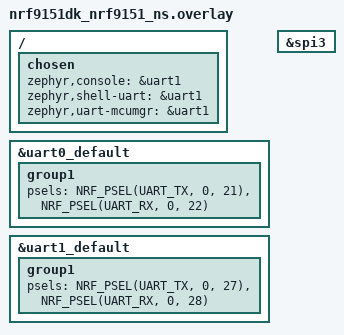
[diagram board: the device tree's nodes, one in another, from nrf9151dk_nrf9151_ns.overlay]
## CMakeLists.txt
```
# SPDX-License-Identifier: Apache-2.0

cmake_minimum_required(VERSION 3.20.0)
find_package(Zephyr REQUIRED HINTS $ENV{ZEPHYR_BASE})
project(gpsdriver)

target_sources(app PRIVATE src/main.c)
target_sources(app PRIVATE src/nmea.c)
target_sources(app PRIVATE src/gps.c)
target_sources(app PRIVATE src/shellnmea.c)
```

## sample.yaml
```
sample:
  name: LC29H GPS Module Sample
  description: |
    Demonstrates communication with LC29H GPS module via UART,
    including NMEA parsing and position data extraction.

tests:
  sample.basic.gps:
    tags:
      - GPS
      - UART
      - NMEA
    filter: dt_enabled_alias_with_parent_compat("uart0", "nordic,nrf-uarte")
    depends_on:
      - uart
      - uart_async_api
    harness: console
    timeout: 120
    min_ram: 16
    min_flash: 64
    integration_platforms:
      - nrf52840dk_nrf52840
      - nrf9160dk_nrf9160
      - nucleo_f411re
    extra_args:
      CONF_FILE: prj.conf
      OVERLAY_CONFIG: overlay-uart.conf

  sample.gps.parsing:
    tags:
      - GPS
      - NMEA
      - PARSING
    filter: dt_enabled_alias_with_parent_compat("uart0", "nordic,nrf-uarte")
    depends_on:
      - uart
      - libc
    harness: console
    integration_platforms:
      - nrf52840dk_nrf52840
      - nrf9160dk_nrf9160
    extra_args:
      CONF_FILE: prj.conf
      OVERLAY_CONFIG: overlay-gps.conf

  sample.gps.performance:
    tags:
      - GPS
      - PERFORMANCE
    filter: dt_enabled_alias_with_parent_compat("uart0", "nordic,nrf-uarte")
    depends_on:
      - timing
      - uart
    harness: console
    timeout: 180
    integration_platforms:
      - nrf52840dk_nrf52840
    extra_args:
      CONF_FILE: prj_performance.conf
```

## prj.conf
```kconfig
#
# Copyright (c) 2020 Nordic Semiconductor ASA
#
# SPDX-License-Identifier: LicenseRef-Nordic-5-Clause
#
# Use GPIO
CONFIG_GPIO=y

# General config
CONFIG_LOG=y
CONFIG_ASSERT=y
CONFIG_DEBUG=y
CONFIG_LOG_DEFAULT_LEVEL=3
CONFIG_STACK_SENTINEL=y

# Basic FPU Configuration
CONFIG_FPU=y

# LibC Configuration (use only ONE)
CONFIG_PICOLIBC=y

# Stacks and heaps
CONFIG_MAIN_STACK_SIZE=8192
CONFIG_HEAP_MEM_POOL_SIZE=32768
CONFIG_SYSTEM_WORKQUEUE_STACK_SIZE=8192

# Base serial support
CONFIG_SERIAL=y
CONFIG_UART_INTERRUPT_DRIVEN=y

# Console on UART0
CONFIG_CONSOLE=y
CONFIG_UART_CONSOLE=y

# Shell
CONFIG_SHELL=y
CONFIG_SHELL_BACKEND_SERIAL=y
CONFIG_SHELL_STACK_SIZE=2048

# For other UART operations
CONFIG_UART_ASYNC_API=y
CONFIG_RING_BUFFER=y

# Disable runtime configure unless needed
# CONFIG_UART_USE_RUNTIME_CONFIGURE=n
```

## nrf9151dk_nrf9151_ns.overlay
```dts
/{
    chosen {
                zephyr,console = &uart1;
                zephyr,shell-uart = &uart1;
                zephyr,uart-mcumgr = &uart1;};
                //zephyr,flash = <&flash0>;
                //zephyr,sram = <&sram0>;
                //zephyr,code-partition = <&slot0_ns_partition>;};
};

&uart0_default {
                    group1 {
                                psels = <NRF_PSEL(UART_TX, 0, 21)>,
                                        <NRF_PSEL(UART_RX, 0, 22)>;};
};
/delete-node/ &{/pin-controller/pwm0_default/group1/};
/delete-node/ &{/pin-controller/pwm0_sleep/group1/};
/delete-node/ &{/pin-controller/uart1_default/group1/};

&uart1_default {
    group1 {
        psels = <NRF_PSEL(UART_TX, 0, 27)>, <NRF_PSEL(UART_RX, 0, 28)>;
    };
};
/delete-node/ &{/pin-controller/uart1_default/group2/};
/delete-node/ &{/pin-controller/uart1_sleep/group1/};
/delete-node/ &{/pin-controller/uart0_default/group2/};
/delete-node/ &{/pin-controller/uart0_sleep/group1/};
/delete-node/ &{/pin-controller/spi3_default/group1/};
/delete-node/ &{/pin-controller/spi3_sleep/group1/};

&spi3 {
    /delete-property/ cs-gpios;
};
/delete-node/ &{/pin-controller/i2c2_sleep/group1/};
/delete-node/ &{/pin-controller/i2c2_default/group1/};
```

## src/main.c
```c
#include <zephyr/kernel.h>
#include <zephyr/drivers/uart.h>
#include <zephyr/drivers/gpio.h>
#include <zephyr/logging/log.h>
#include <zephyr/sys/ring_buffer.h>
#include "shellnmea.h"
#include "nmea.h"

#define RESET_PIN  23
#define WAKEUP_PIN 24
#define VCC_PIN    25
#define SENTENCE_MAX_LEN 128
#define TX_TIMEOUT_MS 1000 

LOG_MODULE_REGISTER(main, CONFIG_LOG_DEFAULT_LEVEL);

const struct device *gpio0_dev = DEVICE_DT_GET(DT_NODELABEL(gpio0));
static const struct device *const uart_dev = DEVICE_DT_GET(DT_NODELABEL(uart0));
static const struct device *const uart_dev1 = DEVICE_DT_GET(DT_NODELABEL(uart1));
static char sentence[SENTENCE_MAX_LEN];
static uint16_t sentence_idx = 0;
static volatile bool tx_done = false;

// Work queue and work item
K_THREAD_STACK_DEFINE(gnss_work_q_stack, 1024);
struct k_work_q gnss_work_q;
struct k_work gnss_work;

// Ring buffer for thread-safe data transfer
RING_BUF_DECLARE(gnss_ring_buf, 256);

#ifdef NMEA_TEST 
// Checksum calculation
static bool verify_nmea_checksum(const char *sentence)
{
    const char *asterisk = strchr(sentence, '*');
    if (!asterisk || asterisk - sentence > SENTENCE_MAX_LEN - 3) 
    {
        return false;
    }

    uint8_t checksum = 0;
    for (const char *p = sentence + 1; p < asterisk; p++) 
    {
        checksum ^= *p;
    }

    char checksum_str[3];
    checksum_str[0] = *(asterisk + 1);
    checksum_str[1] = *(asterisk + 2);
    checksum_str[2] = '\0';

    return checksum == strtoul(checksum_str, NULL, 16);
}

static void parse_nmea_sentence(const char *sentence)
{
    if (!verify_nmea_checksum(sentence)) 
    {
        LOG_WRN("Invalid checksum for: %s", sentence);
        return;
    }

    // Check sentence type
    if (strstr(sentence, "GNRMC") || strstr(sentence, "GPRMC")) {
        LOG_DBG("Unhandled NMEA sentence: %s", sentence);
    }
    else if (strstr(sentence, "GNGGA") || strstr(sentence, "GPGGA")) {
        LOG_DBG("Unhandled NMEA sentence: %s", sentence);
    }
    else {
        LOG_DBG("Unhandled NMEA sentence: %s", sentence);
    }
}
#endif

static void initialize_gps_module(void)
{
    // Configure GPIOs
    if (!device_is_ready(gpio0_dev)) 
    {
        LOG_ERR("GPIO device not ready\n");
    }
 
    // Configure all pins as outputs
    gpio_pin_configure(gpio0_dev, RESET_PIN, GPIO_OUTPUT_INACTIVE);
    gpio_pin_configure(gpio0_dev, WAKEUP_PIN, GPIO_OUTPUT_INACTIVE);
    gpio_pin_configure(gpio0_dev, VCC_PIN, GPIO_OUTPUT_INACTIVE);
 
    // Power sequence for GPS module
    // 1. Power ON GPS (if controlled via GPIO)
    gpio_pin_set(gpio0_dev, VCC_PIN, 1);
    k_msleep(100);  // Wait for power stabilization
 
    // 2. Wake up GPS (active high)
    gpio_pin_set(gpio0_dev, WAKEUP_PIN, 1);
    k_msleep(100);

    // 3. Reset sequence (active low)
    gpio_pin_set(gpio0_dev, RESET_PIN, 0);
    k_msleep(100);  // Hold reset low
    gpio_pin_set(gpio0_dev, RESET_PIN, 1);
    k_msleep(500);  // Wait for module to boot
}

static void gnss_work_cb(struct k_work *work)
{
    uint8_t data;
    size_t len;

    while ((len = ring_buf_get(&gnss_ring_buf, &data, 1)) == 1) 
    {
        if (data == '$') 
        {
            // Start of new sentence
            sentence_idx = 0;
            sentence[sentence_idx++] = data;
        }
        else if ((sentence_idx > 0) && (sentence_idx < SENTENCE_MAX_LEN - 1))
        {
            sentence[sentence_idx++] = data;
            
            // Check for complete sentence
            if (data == '\n') 
            {
                sentence[sentence_idx] = '\0';
                nmea_processing(sentence);
                sentence_idx = 0;
            }
        }
    }
}

static void uart_isr(const struct device *dev, void *user_data)
{
    ARG_UNUSED(user_data);

    if (!uart_irq_update(dev)) return;

    while (uart_irq_rx_ready(dev)) 
    {
        uint8_t byte;
        if (uart_fifo_read(dev, &byte, 1) == 1) 
        {
            if (ring_buf_put(&gnss_ring_buf, &byte, 1) != 1) 
            {
                LOG_WRN("Ring buffer full!");
            }
            k_work_submit_to_queue(&gnss_work_q, &gnss_work);
        }
    }
}

int send_nmea_message(const char *sentence)
{
    if (!device_is_ready(uart_dev)) 
    {
        LOG_ERR("UART device not ready\n");
        return -ENODEV;
    }

#ifdef NMEA_TEST
    size_t len = strlen(sentence);
    int ret;
    int attempts = 0;
    const int max_attempts = 3;

    while (attempts < max_attempts) 
    {
        // Convert timeout to milliseconds as expected by uart_tx
        ret = uart_tx(uart_dev, (const uint8_t *)sentence, len, TX_TIMEOUT_MS);
        
        if (ret == 0) 
        {
            LOG_INF("TX successful: %s", sentence);
            tx_done = true;
            return 0;
        }
        
        k_sleep(K_MSEC(100));  // Short delay between attempts
        attempts++;
    }
    LOG_ERR("Failed to send after %d attempts error: %d", max_attempts, ret);
    return -EIO;
#else
    for (int i = 0; sentence[i] != '\0'; i++) 
    {
        char ch = sentence[i];
        uart_poll_out(uart_dev, ch);

        if (sentence[i] == '\n') 
        {
            return 0;
        }
    }
#endif
    return 0;
}

int main(void)
{
    print_xtracker();

    initialize_gps_module();

    if (!device_is_ready(uart_dev)) 
    {
        LOG_ERR("UART device not ready");
        return 0;
    }

    if (!device_is_ready(uart_dev1)) 
    {
        LOG_ERR("UART1 device not ready");
        return 0;
    }
    
    nmea_init();
    
    // Initialize work queue
    k_work_queue_init(&gnss_work_q);
    k_work_queue_start(&gnss_work_q, gnss_work_q_stack,
                      K_THREAD_STACK_SIZEOF(gnss_work_q_stack),
                      CONFIG_MAIN_THREAD_PRIORITY, NULL);
    k_work_init(&gnss_work, gnss_work_cb);

    // Setup UART interrupt
    uart_irq_callback_user_data_set(uart_dev, uart_isr, NULL);
    uart_irq_rx_enable(uart_dev);
    
#ifdef NMEA_TEST 
    send_nmea_message("$PQTMVER*58\r\n");
    send_nmea_message("$PAIR062,1,1*3F\r\n");
    send_nmea_message("$PAIR062,2,1*3C\r\n");
    send_nmea_message("$PAIR062,3,1*3D\r\n");
    send_nmea_message("$PAIR062,4,1*3A\r\n");
    send_nmea_message("$PAIR062,5,1*3B\r\n");
                   
    if(tx_done == true)
    {
        send_nmea_message("$PQTMRESTOREPAR*13\r\n");
        tx_done = false;
    }

    while (1) 
    {
        k_sleep(K_SECONDS(10));
        LOG_INF("Parser still running...");
    }
#endif
}
```

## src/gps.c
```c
#include <string.h>
#include <math.h>
#include "nmea.h"
#include "gps.h"

#ifdef GPS_TEST
Location berlinLocations[] = {
    // Transport Hubs
    {"Berlin Hauptbahnhof (Central Station)", 52.5251, 13.3694},
    {"Berlin Tegel Airport (TXL)", 52.5597, 13.2877},
    {"Berlin Schönefeld Airport (SXF)", 52.3800, 13.5225},
    {"Berlin Südkreuz Station", 52.4758, 13.3653},
    
    // Landmarks
    {"Brandenburg Gate", 52.5163, 13.3777},
    {"Reichstag Building", 52.5186, 13.3763},
    {"Berlin TV Tower (Fernsehturm)", 52.5208, 13.4095},
    {"Checkpoint Charlie", 52.5075, 13.3904},
    {"Kaiser Wilhelm Memorial Church", 52.5049, 13.3348},
    
    // Parks & Recreation
    {"Tiergarten", 52.5145, 13.3501},
    {"Tempelhofer Feld", 52.4736, 13.4050},
    {"Mauerpark", 52.5440, 13.4020},
    {"Viktoriapark", 52.4886, 13.3814},
    
    // Cultural Sites
    {"Museum Island", 52.5209, 13.4017},
    {"East Side Gallery", 52.5055, 13.4403},
    {"Charlottenburg Palace", 52.5206, 13.2958},
    
    // Neighborhoods
    {"Kreuzberg (Kottbusser Tor)", 52.4990, 13.4184},
    {"Prenzlauer Berg (Kollwitzplatz)", 52.5383, 13.4193},
    {"Neukölln (Hermannplatz)", 52.4811, 13.4239},
    {"Mitte (Nikolaiviertel)", 52.5161, 13.4077},
    
    // Shopping & Dining
    {"Kurfürstendamm (Ku'damm)", 52.5022, 13.3285},
    {"Alexanderplatz", 52.5219, 13.4132},
    {"Potsdamer Platz", 52.5096, 13.3763}
};
#endif
// Number of days in each month for a non-leap year
const int days_in_month[12] = { 31,28,31,30,31,30,31,31,30,31,30,31 };

// Check if a year is a leap year
int is_leap_year(int year) 
{
    return (year % 4 == 0 && (year % 100 != 0 || year % 400 == 0));
}

void timestamp_to_datetime(uint32_t timestamp, uint16_t *year, uint8_t *month, uint8_t *day, uint8_t *hour, uint8_t *minute, uint8_t *second) 
{
    // Unix time starts at 1970-01-01 00:00:00 UTC
    int y = 1970;
    int days;

    // Extract time components from timestamp
    *second = timestamp % 60;
    timestamp /= 60;
    *minute = timestamp % 60;
    timestamp /= 60;
    *hour = timestamp % 24;
    timestamp /= 24;
    days = timestamp;  // total days since 1970-01-01

    // Calculate year
    while (1) 
    {
        int days_in_year = is_leap_year(y) ? 366 : 365;
        if (days >= days_in_year) 
        {
            days -= days_in_year;
            y++;
        } 
        else 
        {
            break;
        }
    }
    *year = y;

    // Calculate month
    int m = 0;
    while (1) 
    {
        int dim = days_in_month[m];
        if (m == 1 && is_leap_year(y)) 
        { // February in leap year
            dim = 29;
        }

        if (days >= dim) 
        {
            days -= dim;
            m++;
        } 
        else 
        {
            break;
        }
    }
    *month = m + 1;  // month is 1-based

    // Remaining days is the day of the month
    *day = days + 1; // day is 1-based
}

// Convert lat e lon to decimals (from deg)
void gps_convert_deg_to_dec(double *latitude, char ns,  double *longitude, char we)
{
    double lat = (ns == 'N') ? *latitude : -1 * (*latitude);
    double lon = (we == 'E') ? *longitude : -1 * (*longitude);

    *latitude = gps_deg_dec(lat);
    *longitude = gps_deg_dec(lon);
}

double gps_deg_dec(double deg_point)
{
    double ddeg;
    double sec = modf(deg_point, &ddeg)*60;
    int deg = (int)(ddeg/100);
    int min = (int)(deg_point-(deg*100));

    double absdlat = round(deg * 1000000.);
    double absmlat = round(min * 1000000.);
    double absslat = round(sec * 1000000.);

    return round(absdlat + (absmlat/60) + (absslat/3600)) /1000000;
}

#ifdef GPS_TEST
void gps_find_location(GNSS_Data *data)
{
    for (int i = 0; i < sizeof(berlinLocations) / sizeof(berlinLocations[0]); i++) 
    {
        double lat = berlinLocations[i].latitude;
        double lon = berlinLocations[i].longitude;

        if (fabs(lat - data->latitude) < 0.0001 && fabs(lon - data->longitude) < 0.0001) 
        {
            printf("Location: %s\n", berlinLocations[i].name);
            return;
        }
    }
    printf("Location not found.\n");
}
#endif
```

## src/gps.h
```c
#ifndef _GPS_H_
#define _GPS_H_

#include <stdio.h>
#include <stdlib.h>
#include <inttypes.h>

#ifdef GPS_TEST
// Define a structure to hold location data
typedef struct 
{
    char name[50];
    double latitude;
    double longitude;
} Location;

void gps_find_location(GNSS_Data *data);
#endif

// Initialize device
extern void gps_init(void);
// Activate device
extern void gps_on(void);
// Turn off device (low-power consumption)
extern void gps_off(void);
void timestamp_to_datetime(uint32_t timestamp, uint16_t *year, uint8_t *month, uint8_t *day, uint8_t *hour, uint8_t *minute, uint8_t *second);

// convert deg to decimal deg latitude, (N/S), longitude, (W/E)
void gps_convert_deg_to_dec(double *, char, double *, char);
double gps_deg_dec(double);

#endif
```

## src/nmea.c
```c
#include <zephyr/device.h>
#include <zephyr/drivers/uart.h>
#include <zephyr/logging/log.h>
#include <zephyr/kernel.h>
#include <string.h>
#include <math.h>
#include "nmea.h"

GNSS_Data *gnss_data = NULL;
TimeStruct UTC_time = {0};

LOG_MODULE_REGISTER(nmea, CONFIG_LOG_DEFAULT_LEVEL);

void nmea_init(void)
{
    gnss_data = malloc(sizeof(GNSS_Data));
    if (gnss_data != NULL) 
    {
        memset(gnss_data, 0, sizeof(GNSS_Data));
    }
}

// Helper function: Convert NMEA (DDMM.MMMM or DDDMM.MMMM) to decimal degrees
static double nmea_to_decimal(double nmea_coord) 
{
    int degrees = (int)(nmea_coord / 100);
    double minutes = nmea_coord - (degrees * 100);
    return degrees + (minutes / 60.0);
}

TimeStruct nmea_parse_time(const char* time_str)
{
    TimeStruct time = {0};
    time.valid = false;

    if ((time_str == NULL) || (strlen(time_str) < 6))
    {
        return time;  // Invalid time format
    }

    // Example time format: "123456.78" (hhmmss.sss)
    char buffer[3] = {0};
    
    // Extract hours (first 2 digits)
    strncpy(buffer, time_str, 2);
    time.hours = atoi(buffer);
    
    // Extract minutes (next 2 digits)
    strncpy(buffer, time_str + 2, 2);
    time.minutes = atoi(buffer);
    
    // Extract seconds (next 2 digits)
    strncpy(buffer, time_str + 4, 2);
    time.seconds = atoi(buffer);
    
    // Find decimal point for hundredths
    const char* decimal_ptr = strchr(time_str, '.');
    if ((decimal_ptr != NULL) && (strlen(decimal_ptr) > 1))
    {
        // Take up to 2 digits after decimal
        strncpy(buffer, decimal_ptr + 1, 2);
        time.millis = atoi(buffer);
    }
    
    // Validate ranges
    if (time.hours < 24 && time.minutes < 60 && time.seconds < 60) 
    {
        time.valid = true;
    }

    // Combine into uint32_t timestamp (hhmmsshh format)
    return time;
}

void nmea_parse_gpgga(const char *nmea)
{
    char *token; 
    char copy[NMEA_MAX_LEN];
    SAFE_STRNCPY(copy, nmea, sizeof(copy));

    token = strtok(copy, ",");
    int field = 0;
    
    while (token != NULL) 
    {
        switch (field) 
        {
            case 1:  // Timestamp (HHMMSS.SSS)
                UTC_time = nmea_parse_time(token);
                break;
            case 2:  // Latitude (DDMM.MMMM)
                gnss_data->latitude = nmea_to_decimal(atof(token));
                break;
            case 3:  // Latitude direction (N/S)
                if (*token == 'S') gnss_data->latitude *= -1;
                break;
            case 4:  // Longitude (DDDMM.MMMM)
                gnss_data->longitude = nmea_to_decimal(atof(token));
                break;
            case 5:  // Longitude direction (E/W)
                if (*token == 'W') gnss_data->longitude *= -1;
                break;
            case 7:  // Satellites in use
                gnss_data->satellites = atoi(token);
                break;
            case 9:  // Altitude (meters)
                gnss_data->altitude = atof(token);
                break;
        }
        token = strtok(NULL, ",");
        field++;
    }
}

void nmea_parse_gprmc(const char *nmea)
{
    char *token;
    char copy[NMEA_MAX_LEN];
    SAFE_STRNCPY(copy, nmea, sizeof(copy));

    token = strtok(copy, ",");
    int field = 0;
    
    while (token != NULL) 
    {
        switch (field) 
        {
            case 1:  // Timestamp (HHMMSS.SSS)
                UTC_time = nmea_parse_time(token);
                break;
            case 2:  // Status (A=active, V=void)
                //gnss_data->status = *token;
                break;
            case 3:  // Latitude (DDMM.MMMM)
                gnss_data->latitude = nmea_to_decimal(atof(token));
                break;
            case 4:  // Latitude direction (N/S)
                if (*token == 'S') gnss_data->latitude *= -1;
                break;
            case 5:  // Longitude (DDDMM.MMMM)
                gnss_data->longitude = nmea_to_decimal(atof(token));
                break;
            case 6:  // Longitude direction (E/W)
                if (*token == 'W') gnss_data->longitude *= -1;
                break;
            case 7:  // Speed (knots)
                // Can be parsed if needed
                break;
        }
        token = strtok(NULL, ",");
        field++;
    }
}

void nmea_parse_gngga(const char *nmea)
{
    char copy[NMEA_MAX_LEN];
    SAFE_STRNCPY(copy, nmea, sizeof(copy));

    char *token = strtok(copy, ",");
    int field = 0;

    while (token != NULL) 
    {
        switch (field) 
        {
            case 1: // Time
                UTC_time = nmea_parse_time(token);
                break;
            case 2: // Latitude
                gnss_data->latitude = nmea_to_decimal(atof(token));
                break;
            case 3: // N/S Indicator
                //gnss_data->ns_indicator = *token;
                //if (*token == 'S') gnss_data->latitude *= -1;
                break;
            case 4: // Longitude
                gnss_data->longitude = nmea_to_decimal(atof(token));
                break;
            case 5: // E/W Indicator
                //gnss_data->ew_indicator = *token;
                //if (*token == 'W') gnss_data->longitude *= -1;
                break;
            case 6: // Fix Quality
                gnss_data->fix_quality = atoi(token);
                break;
            case 7: // Number of Satellites
                //gnss_data->num_satellites = atoi(token);
                break;
            case 8: // HDOP
                //gnss_data->hdop = atof(token);
                break;
            case 9: // Altitude
                gnss_data->altitude = atof(token);
                break;
            case 10: // Altitude Units
                //gnss_data->altitude_units = *token;
                break;
            case 11: // Geoid Separation
                //gnss_data->geoid_separation = atof(token);
                break;
            case 12: // Geoid Units
                //gnss_data->geoid_units = *token;
                break;
            case 13: // Age of Differential Correction
                //SAFE_STRNCPY(gnss_data->age_of_diff_corr, token, sizeof(gnss_data->age_of_diff_corr));
                break;
            case 14: // Diff Ref Station ID
                //SAFE_STRNCPY(gnss_data->diff_ref_station_id, token, sizeof(gnss_data->diff_ref_station_id));
                break;
        }
        token = strtok(NULL, ",");
        field++;
    }
}

#ifdef GSA
void nmea_parse_gpgsa(const char *nmea) 
{
    char *token;
    char copy[NMEA_MAX_LEN];
    SAFE_STRNCPY(copy, nmea, sizeof(copy));

    token = strtok(copy, ",");
    int field = 0;
    
    while (token != NULL) 
    {
        switch (field) 
        {
            case 2:  // Fix Type (1=No fix, 2=2D, 3=3D)
                gnss_data->fix_quality = atoi(token);
                break;
            case 15: // PDOP
                gnss_data->pdop = atof(token);
                break;
            case 16: // HDOP
                gnss_data->hdop = atof(token);
                break;
            case 17: // VDOP
                gnss_data->vdop = atof(token);
                break;
        }
        token = strtok(NULL, ",");
        field++;
    }
}
#endif

#ifdef GSV
void nmea_parse_gpgsv(const char *nmea) 
{
    char *token;
    char copy[NMEA_MAX_LEN];
    SAFE_STRNCPY(copy, nmea, sizeof(copy));

    token = strtok(copy, ",");
    int field = 0;
    int sat_index = 0;
    
    while (token != NULL) 
    {
        switch (field) 
        {
            case 3:  // Total Satellites in View
                gnss_data->total_sats_in_view = atoi(token);
                break;
            case 4:  // Satellite PRN (first of up to 4 per message)
            case 8:  // Second satellite
            case 12: // Third satellite
            case 16: // Fourth satellite
                if (sat_index < 24) 
                {
                    gnss_data->sat_info[sat_index].prn = atoi(token);
                    sat_index++;
                }
                break;
            case 5:  // Elevation (first satellite)
            case 9:  // Second satellite
            case 13: // Third satellite
            case 17: // Fourth satellite
                if (sat_index > 0) 
                {
                    gnss_data->sat_info[sat_index-1].elevation = atoi(token);
                }
                break;
            case 6:  // Azimuth (first satellite)
            case 10: // Second satellite
            case 14: // Third satellite
            case 18: // Fourth satellite
                if (sat_index > 0) 
                {
                    gnss_data->sat_info[sat_index-1].azimuth = atoi(token);
                }
                break;
            case 7:  // SNR (first satellite)
            case 11: // Second satellite
            case 15: // Third satellite
            case 19: // Fourth satellite
                if (sat_index > 0) 
                {
                    gnss_data->sat_info[sat_index-1].snr = atoi(token);
                }
                break;
        }
        token = strtok(NULL, ",");
        field++;
    }
}
#endif

#ifdef VTG
void nmea_parse_gpvtg(const char *nmea) 
{
    char *token;
    char copy[NMEA_MAX_LEN];
    SAFE_STRNCPY(copy, nmea, sizeof(copy));

    token = strtok(copy, ",");
    int field = 0;
    
    while (token != NULL) 
    {
        switch (field) 
        {
            case 1:  // True Course (degrees)
                gnss_data->course = atof(token);
                break;
            case 7:  // Speed (km/h)
                gnss_data->speed = atof(token);
                break;
        }
        token = strtok(NULL, ",");
        field++;
    }
}
#endif

#ifdef GLL
void nmea_parse_gpgll(const char *nmea) 
{
    char *token;
    char copy[NMEA_MAX_LEN];
    SAFE_STRNCPY(copy, nmea, sizeof(copy));

    token = strtok(copy, ",");
    int field = 0;
    
    while (token != NULL) 
    {
        switch (field) 
        {
            case 1:  // Latitude (DDMM.MMMM)
                gnss_data->latitude = atof(token) / 100.0;
                break;
            case 2:  // N/S
                if (*token == 'S') gnss_data->latitude *= -1;
                break;
            case 3:  // Longitude (DDDMM.MMMM)
                gnss_data->longitude = atof(token) / 100.0;
                break;
            case 4:  // E/W
                if (*token == 'W') gnss_data->longitude *= -1;
                break;
            case 5:  // UTC Time (HHMMSS.SSS)
                SAFE_STRNCPY(gnss_data->timestamp, token, sizeof(gnss_data->timestamp));
                break;
            case 6:  // Status (A=Valid, V=Invalid)
                gnss_data->fix_quality = (*token == 'A') ? 1 : 0;
                break;
        }
        token = strtok(NULL, ",");
        field++;
    }
}
#endif
void parse_pqverno(const char *sentence) 
{
    char copy[NMEA_MAX_LEN];
    SAFE_STRNCPY(copy, sentence, sizeof(copy));
    copy[sizeof(copy)-1] = '\0';

    char *token = strtok(copy, ",");
    int index = 0;
    while (token != NULL) 
    {
        if (index == 2) 
        {  // SW Version is usually the 3rd token
            strncpy(gnss_data->firmware_version, token, sizeof(gnss_data->firmware_version));
            gnss_data->firmware_version[sizeof(gnss_data->firmware_version)-1] = '\0';
            break;
        }
        token = strtok(NULL, ",");
        index++;
    }
}

uint8_t nmea_valid_checksum(const char *sentence) 
{
    uint8_t checksum= (uint8_t)strtol(strchr(sentence, '*')+1, NULL, 16);

    char p;
    uint8_t sum = 0;
    ++sentence;
    while ((p = *sentence++) != '*') 
    {
        sum ^= p;
    }

    if (sum != checksum) 
    {
        return NMEA_CHECKSUM_ERROR;
    }

    return _EMPTY;
}

NMEA_MessageType nmea_get_message_type(const char *sentence) 
{
    char *token;
    char copy[NMEA_MAX_LEN];
    SAFE_STRNCPY(copy, sentence, sizeof(copy));
    // Validate checksum first
    uint8_t checksum_status = nmea_valid_checksum(sentence);
    if (checksum_status == NMEA_CHECKSUM_ERROR) 
    {
        return NMEA_CHECKSUM_ERROR;
    }
    
    token = strtok(copy, ",");

    // Detect token type
    if (strstr(token, NMEA_GPGGA_WORD) != NULL) return NMEA_GPGGA;
    if (strstr(token, NMEA_GPRMC_WORD) != NULL) return NMEA_GPRMC;
    if (strstr(token, NMEA_GNGGA_WORD) != NULL) return NMEA_GNGGA;
    //if (strstr(token, NMEA_GPVTG_WORD) != NULL) return NMEA_GPVTG;
    //if (strstr(token, NMEA_GPGSA_WORD) != NULL) return NMEA_GPGSA;
    //if (strstr(token, NMEA_GPGSV_WORD) != NULL) return NMEA_GPGSV;
    //if (strstr(token, NMEA_GPGLL_WORD) != NULL) return NMEA_GPGLL;
    //if (strstr(token, NMEA_GPZDA_WORD) != NULL) return NMEA_GPZDA;
    //if (strstr(token, NMEA_GPGST_WORD) != NULL) return NMEA_GPGST;
    //if (strstr(token, NMEA_GPGNS_WORD) != NULL) return NMEA_GPGNS;
    if (strstr(token, NMEA_PQVERNO_WORD) != NULL) return NMEA_PQVERNO;

    return NMEA_UNKNOWN;
}

static void handle_unknown(const char *sentence) 
{
    char buffer[16]; // Local buffer to store the sentence type
 
    // Extract the first part of the sentence (e.g., "$GPGGA")
    const char *delimiter = strchr(sentence, ','); // Find the first comma
    if (delimiter != NULL)
    {
        size_t length = delimiter - sentence; // Calculate the length of the sentence type
        if (length >= sizeof(buffer))
        {
            length = sizeof(buffer) - 1; // Ensure we don't overflow the buffer
        }
        strncpy(buffer, sentence, length); // Copy the sentence type to buffer
        buffer[length] = '\0'; // Null-terminate the string
    } 
    else 
    {
        strncpy(buffer, sentence, sizeof(buffer) - 1); // Handle case with no comma
        buffer[sizeof(buffer) - 1] = '\0'; // Null-terminate the string
    }
 
    LOG_DBG("UNKNOWN: %s\n", buffer); // Print the extracted sentence type
}

/* NMEA Processing */
void nmea_processing(const char *sentence)
{
    uint8_t msgtype;
     
    // Dispatch to appropriate handler
    msgtype = nmea_get_message_type(sentence);
    if (msgtype == NMEA_CHECKSUM_ERROR) 
    {
        return;
    }
    
    switch (msgtype) 
    {
        case NMEA_GPGGA:
            nmea_parse_gpgga(sentence);
        break;
        case NMEA_GPRMC:
            nmea_parse_gprmc(sentence);
        break;
        case NMEA_GNGGA:
            nmea_parse_gngga(sentence);
        break;
        case NMEA_GPGLL:
        case NMEA_GPGSV:
        case NMEA_GPGSA:
        case NMEA_GPGST:
        case NMEA_GPZDA:
        case NMEA_GPGNS:
            handle_unknown(sentence);
        break;
        case NMEA_PQVERNO:
            parse_pqverno(sentence);
        break;
        default:
            // Unhandled message type
            handle_unknown(sentence);
        break;
    }
}

void nmea_enable_pps_sync(void)
{
	//uint8_t buffer[] = NMEA_ENABLE_PPS_SYNC;
	//send_nmea_message(buffer);
}

void nmea_hot_restart(void)
{
	//uint8_t buffer[] = NMEA_HOT_RST_CMD;
	//send_nmea_message(buffer);
}

void nmea_factory_reset(void)
{
	//uint8_t buffer[] = NMEA_FCOLD_RST_CMD;
	//send_nmea_message(buffer);
}

void nmea_standby(void)
{
	//uint8_t buffer[] = NMEA_SET_STDBY_CMD;
	//send_nmea_message(buffer);
}
```

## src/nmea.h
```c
#ifndef _NMEA_H_
#define _NMEA_H_

#include <stdio.h>
#include <stdlib.h>
#include <inttypes.h>
#include <stdbool.h>

/* NMEA Command Macros */
#define _EMPTY 0x00
#define _COMPLETED 0x03
#define NMEA_MESSAGE_ERR 0xC0
#define NMEA_MAX_LEN 82

/* LC29H-Specific Commands */
#define LC29H_SAVE_CFG         "$PQTMSAVEPAR*5A\r\n" 
#define LC29H_VERNO_CMD        "$PQTMVERNO*58\r\n"
#define LC29H_SET_BAUD         "$PAIR864,0,0,115200*\r\n"
#define LC29H_UPDATE_RATE_CMD  "$PQTXT,W,UPDATE,100*2F\r\n"
#define LC29H_DEFAULT8CFG      "$PQTMRESTOREPAR*13\r\n" 
#define LC29H_ENABLE_GGA       "$PAIR062,0,1*3B\r\n"
#define LC29H_ENABLE_GLL       "$PAIR062,1,1*3A\r\n"
#define LC29H_ENABLE_GSA       "$PAIR062,2,1*3F\r\n"
#define LC29H_ENABLE_GSV       "$PAIR062,3,1*3E\r\n"
#define LC29H_ENABLE_RMC       "$PAIR062,4,1*3D\r\n"
#define LC29H_ENABLE_VTG       "$PAIR062,5,1*38\r\n"
#define LC29H_DISABLE_GGA      "$PAIR062,0,0*3A\r\n"
#define LC29H_DISABLE_GLL      "$PAIR062,1,0*3B\r\n"  
#define LC29H_DISABLE_GSA      "$PAIR062,2,0*3C\r\n"  
#define LC29H_DISABLE_GSV      "$PAIR062,3,0*3D\r\n"  
#define LC29H_DISABLE_RMC      "$PAIR062,4,0*3E\r\n"  
#define LC29H_DISABLE_VTG      "$PAIR062,5,0*3B\r\n"

/* NMEA Sentence Enable Commands */
#define NMEA_SET_STDBY_CMD     "$PMTK161,0*28\r\n"     // Enter standby mode
#define NMEA_HOT_RST_CMD       "$PMTK101*32\r\n"       // Hot reset (fastest, keeps ephemeris)
#define NMEA_WARM_RST_CMD      "$PMTK102*31\r\n"       // Warm reset (keeps almanac)
#define NMEA_COLD_RST_CMD      "$PMTK103*30\r\n"       // Cold reset (clears ephemeris, keeps almanac)
#define NMEA_FCOLD_RST_CMD     "$PMTK104*37\r\n"       // Factory cold reset (full reset)
#define NMEA_CLR_FLASH_CMD     "$PMTK120*31\r\n"       // Clear flash data
#define NMEA_CLEAR_ORBIT_CMD   "$PMTK127*36\r\n"       // Clear assisted ephemeris (AGPS)
#define NMEA_FIXINT_CMD        "$PMTK220,1000*1F\r\n"  // Fix interval (1000 ms = 1 Hz)
#define NMEA_FIXINT_5HZ_CMD    "$PMTK220,200*2C\r\n"   // Fix interval (200 ms = 5 Hz)
#define NMEA_FIXINT_10HZ_CMD   "$PMTK220,100*2F\r\n"   // Fix interval (100 ms = 10 Hz)
#define NMEA_ENABLE_PPS_SYNC   "$PMTK255,1*2D\r\n"     // Enable PPS Sync
#define NMEA_DISABLE_PPS_SYNC  "$PMTK255,0*2C\r\n"     // Disable PPS Sync

// NMEA Sentence Identifiers
#define NMEA_GPGGA_WORD "$GPGGA"
#define NMEA_GPRMC_WORD "$GPRMC"
#define NMEA_GPVTG_WORD "$GPVTG"
#define NMEA_GPGSA_WORD "$GPGSA"
#define NMEA_GPGSV_WORD "$GPGSV"
#define NMEA_GPGLL_WORD "$GPGLL"
#define NMEA_GPZDA_WORD "$GPZDA"
#define NMEA_GPGST_WORD "$GPGST"
#define NMEA_GPGNS_WORD "$GPGNS"
#define NMEA_GNGGA_WORD "$GNGGA"
#define NMEA_PQVERNO_WORD "$PQTMVERNO"

#define SAFE_STRNCPY(dest, src, size) \
    do { \
        strncpy(dest, src, size - 1); \
        dest[size - 1] = '\0'; \
    } while (0)

    typedef struct 
{
    uint8_t hours;      // 0-23
    uint8_t minutes;    // 0-59
    uint8_t seconds;    // 0-59
    uint16_t millis;    // 0-999
    bool valid;         // true if time was parsed successfully
} TimeStruct;

extern TimeStruct UTC_time;

/* GNSS Data Structure */
typedef struct 
{
    // Common Fields (from GGA/RMC)
    double latitude;
    double longitude;
    float altitude;
    float speed;         // in km/h (from RMC/VTG)
    float course;        // in degrees (from RMC/VTG)
    uint8_t fix_quality;     // 0=invalid, 1=GPS, 2=DGPS, etc. (from GGA/GSA)
    uint8_t satellites;      // Number of satellites in use (from GGA/GSA)
    uint32_t timestamp;  // UTC time (HHMMSS.SS)
    char date[10];       // UTC date (DDMMYY)
#ifdef GSA
    // Additional Fields (from other messages)
    float hdop;          // Horizontal Dilution of Precision (from GSA)
    float vdop;          // Vertical DOP (from GSA)
    float pdop;          // Position DOP (from GSA)
    float mag_var;       // Magnetic variation (from RMC)
    char mode_indicator; // NMEA 4.1+ mode (A=Autonomous, D=DGPS, etc.) (from GNS/RMC)
    char nav_status[20]; // Navigation status (from GNS)
#endif
#ifdef GSV
    // GSV (Satellites in View)
    int total_sats_in_view;
    struct {
        int prn;         // Satellite PRN number
        int elevation;  // Elevation in degrees
        int azimuth;    // Azimuth in degrees
        int snr;        // Signal-to-noise ratio (dB)
    } sat_info[24];     // Max 24 satellites (4 per GSV sentence)
#endif
#ifdef GST
    // GST (GNSS Pseudorange Errors)
    float std_latitude;  // Standard deviation of latitude error (m)
    float std_longitude; // Standard deviation of longitude error (m)
    float std_altitude;  // Standard deviation of altitude error (m)
#endif
#ifdef ZDA
    // ZDA (UTC Time & Date)
    int utc_year;        // Full year (e.g., 2025)
    int utc_month;       // Month (1-12)
    int utc_day;         // Day (1-31)
    int utc_hour;        // Hour (0-23)
    int utc_min;         // Minute (0-59)
    int utc_sec;         // Second (0-59)
#endif
#ifdef GRS
    // GRS (GNSS Range Residuals)
    float range_residuals[12]; // Range residuals for each satellite (m)
#endif
    // Firmware Info
    char firmware_version[32];
} GNSS_Data;

extern GNSS_Data *gnss_data;

// NMEA Message Types
typedef enum 
{
    NMEA_UNKNOWN = 0,
    NMEA_GPGGA,
    NMEA_GPRMC,
    NMEA_GPVTG,
    NMEA_GPGSA,
    NMEA_GPGSV,
    NMEA_GPGLL,
    NMEA_GPZDA,
    NMEA_GPGST,
    NMEA_GPGNS,
    NMEA_GNGGA,
    NMEA_PQVERNO,
    NMEA_CHECKSUM_ERROR
} NMEA_MessageType;

typedef struct 
{
    uint8_t hours;
    uint8_t minutes;
    uint8_t seconds;
} NMEA_Time;

typedef struct 
{
    uint8_t day;
    uint8_t month;
    uint16_t year;  // 2-digit or 4-digit year depending on needs
} NMEA_Date;

void nmea_processing(const char *message);
int send_nmea_message(const char *sentence);
void nmea_init(void);
#endif
```

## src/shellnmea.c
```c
#include <zephyr/kernel.h>
#include <zephyr/shell/shell.h>
#include <string.h>
#include "shellnmea.h"
#include "nmea.h"
#include "gps.h"

LOG_MODULE_REGISTER(shellnmea, LOG_LEVEL_INF);

/* Shell command handler: Request software version from LH29C */
static int cmd_swversion(const struct shell *shell, size_t argc, char **argv) 
{
    ARG_UNUSED(argc);
    ARG_UNUSED(argv);
    
    if (send_nmea_message(LC29H_VERNO_CMD) != 0) 
	{
        shell_error(shell, "Failed to send version request");
        return -EIO;
    }
    
    shell_print(shell, "Requested software version from LH29C");
    return 0;
}

static int cmd_show_swversion(const struct shell *shell, size_t argc, char **argv)
{
    ARG_UNUSED(argc);
    ARG_UNUSED(argv);

    if (gnss_data == NULL || strlen(gnss_data->firmware_version) == 0) 
    {
        shell_warn(shell, "Software version not available.");
    }
    else 
    {
        shell_print(shell, "Firmware version: %s", gnss_data->firmware_version);
    }
    return 0;
}

static uint8_t shell_checksum(const char *sentence)
{
    uint8_t checksum = 0;
    sentence++; 
    while (*sentence && *sentence != '*') {
        checksum ^= *sentence++;
    }
    return checksum;
}

/* Shell command handler: Custom NMEA command forwarding */
static int cmd_send_nmea(const struct shell *shell, size_t argc, char **argv)
{
    if (argc != 2) 
    {
        shell_error(shell, "Usage: send_nmea <NMEA_CMD_NO_CHECKSUM>");
        shell_error(shell, "Example: send_nmea $PUBX,00");
        return -EINVAL;
    }

    const char *base = argv[1];

    // Validate base sentence
    if (strlen(base) < 6 || base[0] != '$') 
    {
        shell_error(shell, "Invalid NMEA command format");
        return -EINVAL;
    }

    uint8_t checksum = shell_checksum(base);

    // Format full sentence with checksum and termination
    char cmd_buf[128];
    snprintf(cmd_buf, sizeof(cmd_buf), "%s*%02X\r\n", base, checksum);

    if (send_nmea_message(cmd_buf) != 0) 
    {
        shell_error(shell, "Failed to send NMEA command");
        return -EIO;
    }

    shell_print(shell, "Sent to LH29C: %s", cmd_buf);
    return 0;
}

static int cmd_read_nmea(const struct shell *shell, size_t argc, char **argv)
{
    ARG_UNUSED(argc);
    ARG_UNUSED(argv);
    if (!UTC_time.valid) 
    {
        shell_error(shell,"Invalid time\n");
    }
    
    shell_print(shell,"%-25s: %02u:%02u:%02u.%03u\n", "UTC Time", UTC_time.hours, UTC_time.minutes, UTC_time.seconds, UTC_time.millis);
    shell_print(shell,"%-25s: %.06lf\n", "The Latitude is", gnss_data->latitude);
    shell_print(shell,"%-25s: %.06lf\n", "The Longitude is", gnss_data->longitude);
    shell_print(shell,"%-25s: %.01lf\n", "The Altitude is", (double)gnss_data->altitude);
    shell_print(shell,"https://www.google.com/maps?q=%.06lf,%.06lf&z=18\n", gnss_data->latitude, gnss_data->longitude);
    
    return 0;
}

/* Shell command registration */
SHELL_CMD_REGISTER(swversion, NULL, "Request software version from LH29C", cmd_swversion);
SHELL_CMD_REGISTER(show_swversion, NULL, "Software version is", cmd_show_swversion);
SHELL_CMD_ARG_REGISTER(send_nmea, NULL, "Send custom NMEA command to LH29C (include $ and *CRC)", cmd_send_nmea, 2, 0);
SHELL_CMD_REGISTER(read_nmea, NULL, "Request the GPS data from LH29C", cmd_read_nmea);

void print_banner_char(char ch, int row) 
{
    // Define 5x5 style patterns for each letter (row-wise)
    const char *X[5] = {
        "*   *", " * * ", "  *  ", " * * ", "*   *"
    };
    const char *T[5] = {
        "*****", "  *  ", "  *  ", "  *  ", "  *  "
    };
    const char *R[5] = {
        "**** ", "*   *", "**** ", "*  * ", "*   *"
    };
    const char *A[5] = {
        " *** ", "*   *", "*****", "*   *", "*   *"
    };
    const char *C[5] = {
        " ****", "*    ", "*    ", "*    ", " ****"
    };
    const char *K[5] = {
        "*   *", "*  * ", "***  ", "*  * ", "*   *"
    };
    const char *E[5] = {
        "*****", "*    ", "**** ", "*    ", "*****"
    };

    const char **pattern = NULL;
    switch (ch) {
        case 'X': case 'x': pattern = X; break;
        case 'T': case 't': pattern = T; break;
        case 'R': case 'r': pattern = R; break;
        case 'A': case 'a': pattern = A; break;
        case 'C': case 'c': pattern = C; break;
        case 'K': case 'k': pattern = K; break;
        case 'E': case 'e': pattern = E; break;
        default: pattern = T; break; // fallback
    }

    printf("%s ", pattern[row]);
}

void print_xtracker(void) 
{
    char str[] = "xtracker";

    for (int row = 0; row < 5; row++) 
    {
        for (int i = 0; i < strlen(str); i++) 
        {
            print_banner_char(str[i], row);
        }
        printf("\n");
    }
}
```

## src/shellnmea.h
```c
#ifndef _SHELLNMEA_H_
#define _SHELLNMEA_H_

void print_xtracker(void);
 
#endif
```
